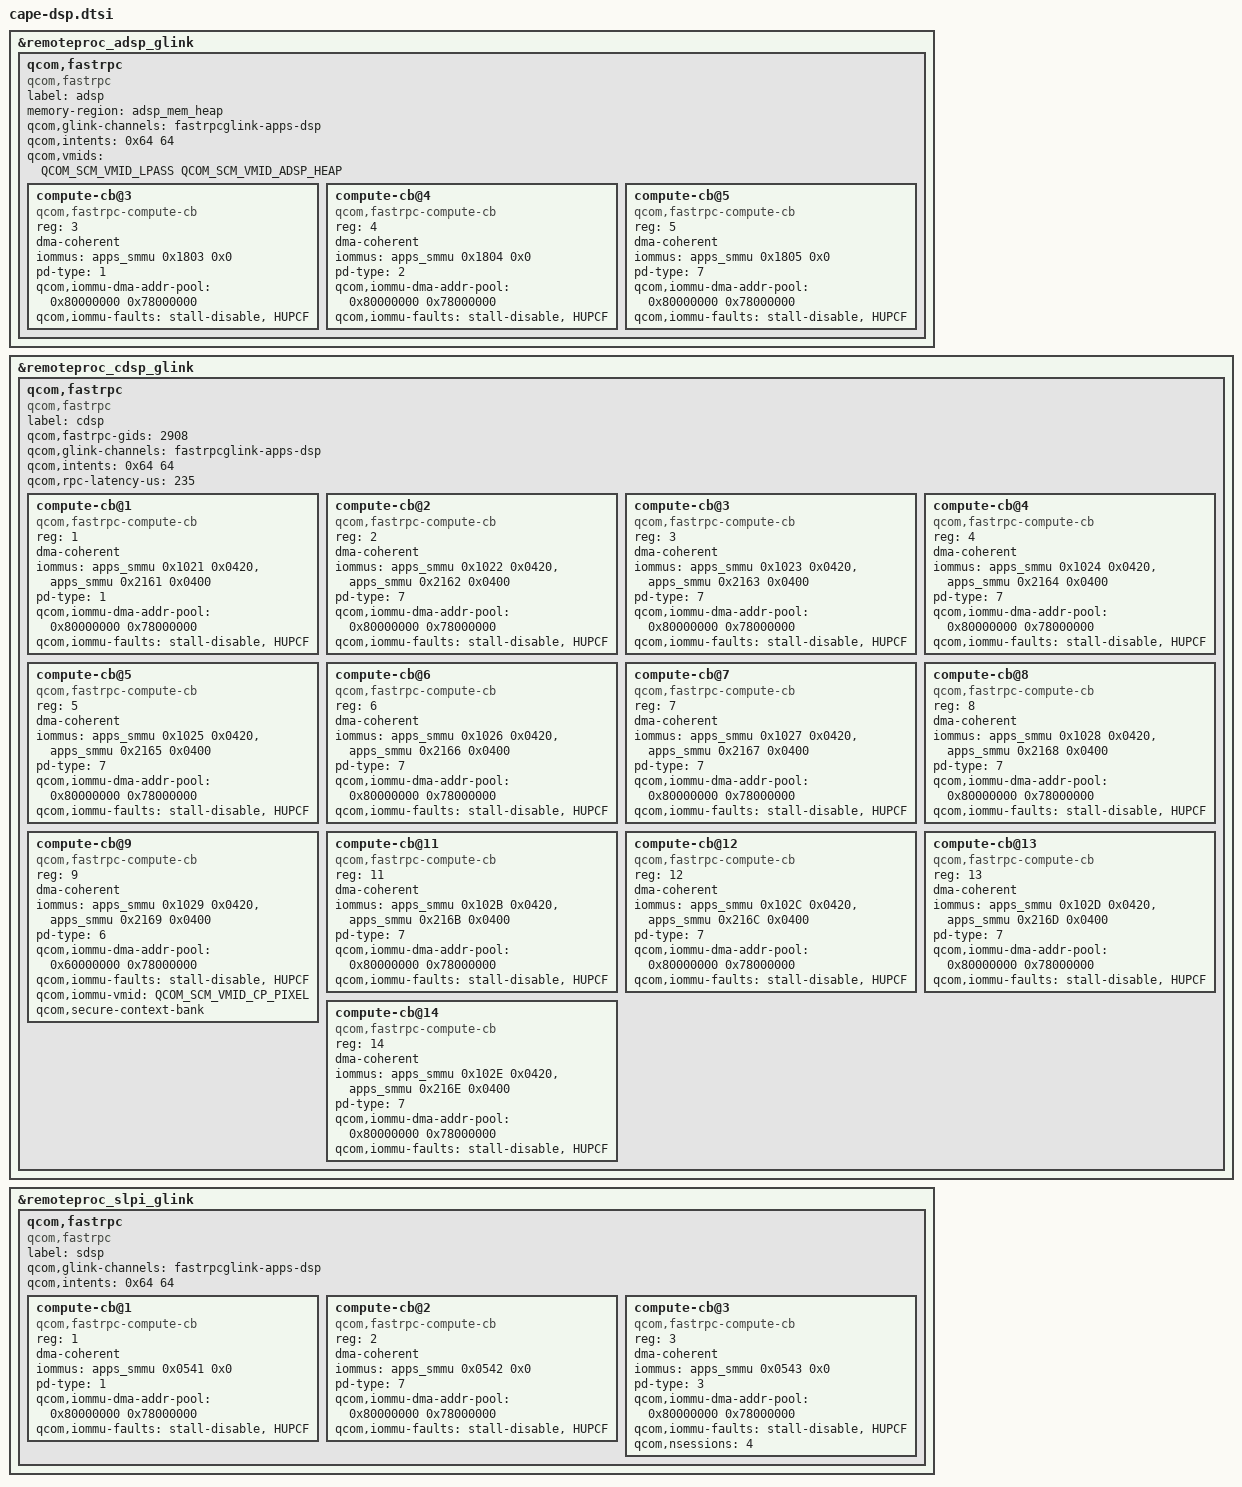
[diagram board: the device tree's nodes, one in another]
// SPDX-License-Identifier: BSD-3-Clause

#include <dt-bindings/firmware/qcom,scm.h>

&remoteproc_adsp_glink {
	qcom,fastrpc {
		compatible = "qcom,fastrpc";
		label = "adsp";
		memory-region = <&adsp_mem_heap>;

		qcom,glink-channels = "fastrpcglink-apps-dsp";
		qcom,intents = <0x64 64>;
		qcom,vmids = <QCOM_SCM_VMID_LPASS QCOM_SCM_VMID_ADSP_HEAP>;

		compute-cb@3 {
			compatible = "qcom,fastrpc-compute-cb";
			reg = <3>;

			dma-coherent;
			iommus = <&apps_smmu 0x1803 0x0>;

			pd-type = <1>; /* ROOT_PD */
			qcom,iommu-dma-addr-pool = <0x80000000 0x78000000>;
			qcom,iommu-faults = "stall-disable", "HUPCF";
		};

		compute-cb@4 {
			compatible = "qcom,fastrpc-compute-cb";
			reg = <4>;

			dma-coherent;
			iommus = <&apps_smmu 0x1804 0x0>;

			pd-type = <2>; /* AUDIO_STATICPD */
			qcom,iommu-dma-addr-pool = <0x80000000 0x78000000>;
			qcom,iommu-faults = "stall-disable", "HUPCF";
		};

		compute-cb@5 {
			compatible = "qcom,fastrpc-compute-cb";
			reg = <5>;

			dma-coherent;
			iommus = <&apps_smmu 0x1805 0x0>;

			pd-type = <7>; /* USERPD */
			qcom,iommu-dma-addr-pool = <0x80000000 0x78000000>;
			qcom,iommu-faults = "stall-disable", "HUPCF";
		};
	};
};

&remoteproc_cdsp_glink {
	qcom,fastrpc {
		compatible = "qcom,fastrpc";
		label = "cdsp";

		qcom,fastrpc-gids = <2908>;
		qcom,glink-channels = "fastrpcglink-apps-dsp";
		qcom,intents = <0x64 64>;
		qcom,rpc-latency-us = <235>;

		compute-cb@1 {
			compatible = "qcom,fastrpc-compute-cb";
			reg = <1>;

			dma-coherent;
			iommus = <&apps_smmu 0x1021 0x0420>,
				 <&apps_smmu 0x2161 0x0400>;

			pd-type = <1>; /* ROOT_PD */
			qcom,iommu-dma-addr-pool = <0x80000000 0x78000000>;
			qcom,iommu-faults = "stall-disable", "HUPCF";
		};

		compute-cb@2 {
			compatible = "qcom,fastrpc-compute-cb";
			reg = <2>;

			dma-coherent;
			iommus = <&apps_smmu 0x1022 0x0420>,
				 <&apps_smmu 0x2162 0x0400>;

			pd-type = <7>; /* USERPD */
			qcom,iommu-dma-addr-pool = <0x80000000 0x78000000>;
			qcom,iommu-faults = "stall-disable", "HUPCF";
		};

		compute-cb@3 {
			compatible = "qcom,fastrpc-compute-cb";
			reg = <3>;

			dma-coherent;
			iommus = <&apps_smmu 0x1023 0x0420>,
				 <&apps_smmu 0x2163 0x0400>;

			pd-type = <7>; /* USERPD */
			qcom,iommu-dma-addr-pool = <0x80000000 0x78000000>;
			qcom,iommu-faults = "stall-disable", "HUPCF";
		};

		compute-cb@4 {
			compatible = "qcom,fastrpc-compute-cb";
			reg = <4>;

			dma-coherent;
			iommus = <&apps_smmu 0x1024 0x0420>,
				 <&apps_smmu 0x2164 0x0400>;

			pd-type = <7>; /* USERPD */
			qcom,iommu-dma-addr-pool = <0x80000000 0x78000000>;
			qcom,iommu-faults = "stall-disable", "HUPCF";
		};

		compute-cb@5 {
			compatible = "qcom,fastrpc-compute-cb";
			reg = <5>;

			dma-coherent;
			iommus = <&apps_smmu 0x1025 0x0420>,
				 <&apps_smmu 0x2165 0x0400>;

			pd-type = <7>; /* USERPD */
			qcom,iommu-dma-addr-pool = <0x80000000 0x78000000>;
			qcom,iommu-faults = "stall-disable", "HUPCF";
		};

		compute-cb@6 {
			compatible = "qcom,fastrpc-compute-cb";
			reg = <6>;

			dma-coherent;
			iommus = <&apps_smmu 0x1026 0x0420>,
				 <&apps_smmu 0x2166 0x0400>;

			pd-type = <7>; /* USERPD */
			qcom,iommu-dma-addr-pool = <0x80000000 0x78000000>;
			qcom,iommu-faults = "stall-disable", "HUPCF";
		};

		compute-cb@7 {
			compatible = "qcom,fastrpc-compute-cb";
			reg = <7>;

			dma-coherent;
			iommus = <&apps_smmu 0x1027 0x0420>,
				 <&apps_smmu 0x2167 0x0400>;

			pd-type = <7>; /* USERPD */
			qcom,iommu-dma-addr-pool = <0x80000000 0x78000000>;
			qcom,iommu-faults = "stall-disable", "HUPCF";
		};

		compute-cb@8 {
			compatible = "qcom,fastrpc-compute-cb";
			reg = <8>;

			dma-coherent;
			iommus = <&apps_smmu 0x1028 0x0420>,
				 <&apps_smmu 0x2168 0x0400>;

			pd-type = <7>; /* USERPD */
			qcom,iommu-dma-addr-pool = <0x80000000 0x78000000>;
			qcom,iommu-faults = "stall-disable", "HUPCF";
		};

		compute-cb@9 {
			compatible = "qcom,fastrpc-compute-cb";
			reg = <9>;

			dma-coherent;
			iommus = <&apps_smmu 0x1029 0x0420>,
				 <&apps_smmu 0x2169 0x0400>;

			pd-type = <6>; /* CPZ_USERPD */
			qcom,iommu-dma-addr-pool = <0x60000000 0x78000000>;
			qcom,iommu-faults = "stall-disable", "HUPCF";
			qcom,iommu-vmid = <QCOM_SCM_VMID_CP_PIXEL>;
			qcom,secure-context-bank;
		};

		compute-cb@11 {
			compatible = "qcom,fastrpc-compute-cb";
			reg = <11>;

			dma-coherent;
			iommus = <&apps_smmu 0x102B 0x0420>,
				 <&apps_smmu 0x216B 0x0400>;

			pd-type = <7>; /* USERPD */
			qcom,iommu-dma-addr-pool = <0x80000000 0x78000000>;
			qcom,iommu-faults = "stall-disable", "HUPCF";
		};

		compute-cb@12 {
			compatible = "qcom,fastrpc-compute-cb";
			reg = <12>;

			dma-coherent;
			iommus = <&apps_smmu 0x102C 0x0420>,
				 <&apps_smmu 0x216C 0x0400>;

			pd-type = <7>; /* USERPD */
			qcom,iommu-dma-addr-pool = <0x80000000 0x78000000>;
			qcom,iommu-faults = "stall-disable", "HUPCF";
		};

		compute-cb@13 {
			compatible = "qcom,fastrpc-compute-cb";
			reg = <13>;

			dma-coherent;
			iommus = <&apps_smmu 0x102D 0x0420>,
				 <&apps_smmu 0x216D 0x0400>;

			pd-type = <7>; /* USERPD */
			qcom,iommu-dma-addr-pool = <0x80000000 0x78000000>;
			qcom,iommu-faults = "stall-disable", "HUPCF";
		};

		compute-cb@14 {
			compatible = "qcom,fastrpc-compute-cb";
			reg = <14>;

			dma-coherent;
			iommus = <&apps_smmu 0x102E 0x0420>,
				 <&apps_smmu 0x216E 0x0400>;

			pd-type = <7>; /* USERPD */
			qcom,iommu-dma-addr-pool = <0x80000000 0x78000000>;
			qcom,iommu-faults = "stall-disable", "HUPCF";
		};
	};
};

&remoteproc_slpi_glink {
	qcom,fastrpc {
		compatible = "qcom,fastrpc";
		label = "sdsp";

		qcom,glink-channels = "fastrpcglink-apps-dsp";
		qcom,intents = <0x64 64>;

		compute-cb@1 {
			compatible = "qcom,fastrpc-compute-cb";
			reg = <1>;

			dma-coherent;
			iommus = <&apps_smmu 0x0541 0x0>;

			pd-type = <1>; /* ROOT_PD */
			qcom,iommu-dma-addr-pool = <0x80000000 0x78000000>;
			qcom,iommu-faults = "stall-disable", "HUPCF";
		};

		compute-cb@2 {
			compatible = "qcom,fastrpc-compute-cb";
			reg = <2>;

			dma-coherent;
			iommus = <&apps_smmu 0x0542 0x0>;

			pd-type = <7>; /* USERPD */
			qcom,iommu-dma-addr-pool = <0x80000000 0x78000000>;
			qcom,iommu-faults = "stall-disable", "HUPCF";
		};

		compute-cb@3 {
			compatible = "qcom,fastrpc-compute-cb";
			reg = <3>;

			dma-coherent;
			iommus = <&apps_smmu 0x0543 0x0>;

			pd-type = <3>; /* SENSORS_STATICPD */
			qcom,iommu-dma-addr-pool = <0x80000000 0x78000000>;
			qcom,iommu-faults = "stall-disable", "HUPCF";
			qcom,nsessions = <4>;
		};
	};
};
